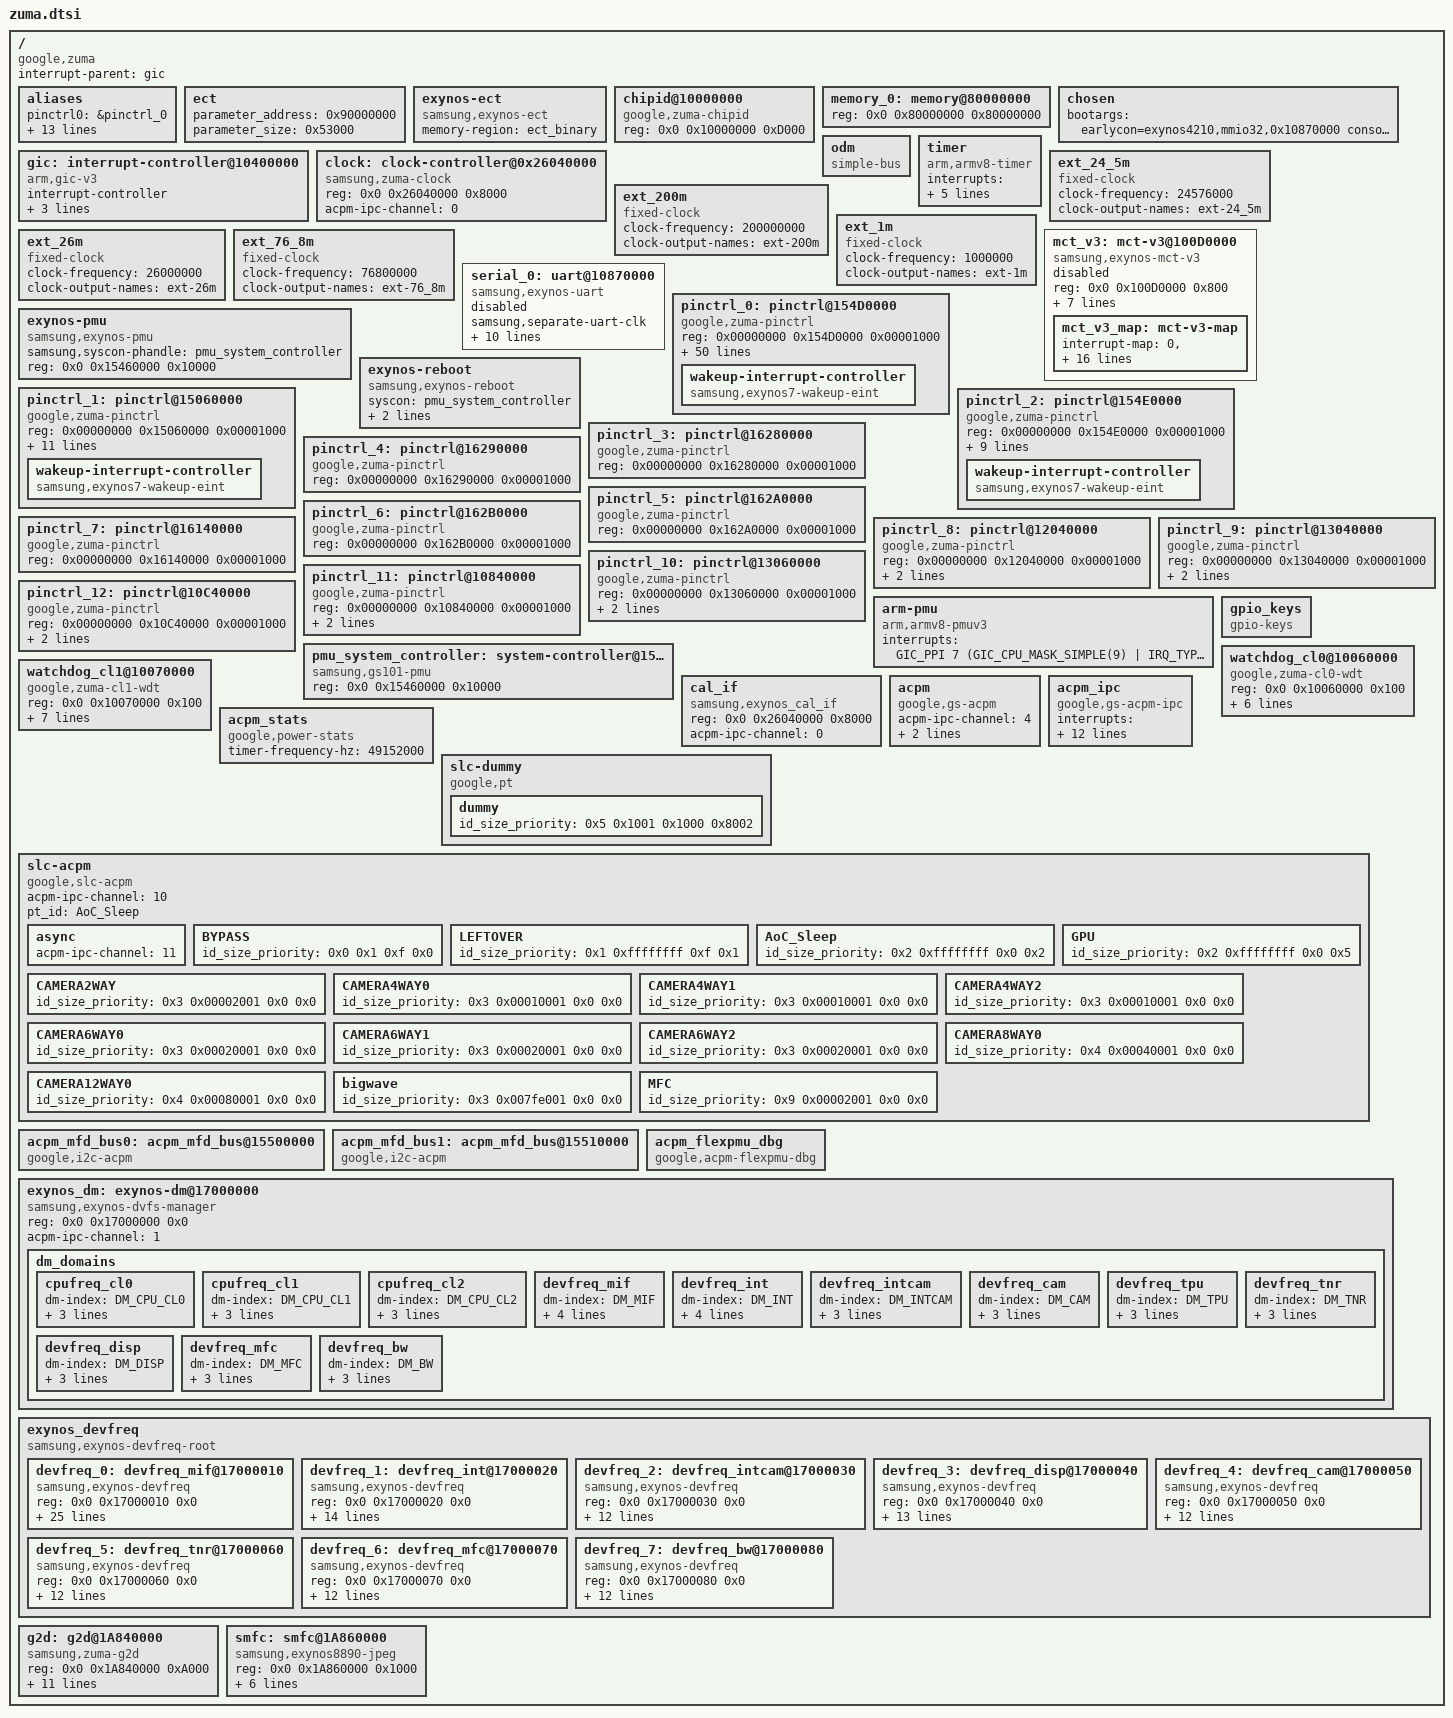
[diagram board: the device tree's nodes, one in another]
// SPDX-License-Identifier: GPL-2.0-only
/*
 * Copyright 2022 Google LLC.
 *
 */

#include <dt-bindings/gpio/gpio.h>
#include <dt-bindings/interrupt-controller/arm-gic.h>
#include <dt-bindings/interrupt-controller/zuma.h>
#include <dt-bindings/clock/zuma.h>
#include <dt-bindings/soc/google/zuma-dm.h>
#include <dt-bindings/soc/google/zuma-devfreq.h>
#include <dt-bindings/soc/google/zuma-pm-qos.h>
#include "zuma-rmem.dtsi"
#include "gs101-trusty.dtsi"
#include "zuma-gpu.dtsi"
#include "zuma-cpu.dtsi"
#include "zuma-bigw.dtsi"
#include "zuma-bts.dtsi"
#include "zuma-drm-dpu.dtsi"
#include "zuma-dma-heap.dtsi"
#include "zuma-gsa.dtsi"
#include "zuma-isp.dtsi"
#include "zuma-pinctrl.dtsi"
#include "zuma-usi.dtsi"
#include "zuma-debug.dtsi"
#include "zuma-aoc.dtsi"
#include "zuma-ufs.dtsi"
#include "zuma-usb.dtsi"
#include "zuma-pm-domains.dtsi"
#include "zuma-mfc.dtsi"
#include "zuma-tpu.dtsi"
#include "zuma-pcie.dtsi"
#include "zuma-gxp.dtsi"
#include "zuma-audio.dtsi"
#include "zuma-s2mpu.dtsi"

/ {
	compatible = "google,zuma";
	interrupt-parent = <&gic>;
	#address-cells = <2>;
	#size-cells = <1>;

	aliases {
		pinctrl0 = &pinctrl_0;
		pinctrl1 = &pinctrl_1;
		pinctrl2 = &pinctrl_2;
		pinctrl3 = &pinctrl_3;
		pinctrl4 = &pinctrl_4;
		pinctrl5 = &pinctrl_5;
		pinctrl6 = &pinctrl_6;
		pinctrl7 = &pinctrl_7;
		pinctrl8 = &pinctrl_8;
		pinctrl9 = &pinctrl_9;
		pinctrl10 = &pinctrl_10;
		pinctrl11 = &pinctrl_11;
		pinctrl12 = &pinctrl_12;
		uart0 = &serial_0;

	};

        ect {
                parameter_address = <0x90000000>;
                parameter_size = <0x53000>;
        };

        exynos-ect {
                compatible = "samsung,exynos-ect";
                memory-region = <&ect_binary>;
        };

	chipid@10000000 {
		compatible = "google,zuma-chipid";
		reg = <0x0 0x10000000 0xD000>;
	};

	memory_0: memory@80000000 {
		device_type = "memory";
		reg = <0x0 0x80000000 0x80000000>;
	};

	chosen: chosen {
		bootargs = "earlycon=exynos4210,mmio32,0x10870000 console=ttySAC0,115200n8 root=/dev/ram0 rw clocksource=arch_sys_counter androidboot.hardware=zuma androidboot.hardware.platform=zuma androidboot.selinux=permissive androidboot.debug_level=0x4948 clk_ignore_unused loop.max_part=7 coherent_pool=4M firmware_class.path=/vendor/firmware log_buf_len=256K irqaffinity=0rcupdate.rcu_expedited=1 printk.devkmsg=on swiotlb=noforce androidboot.slot_suffix=_a androidboot.secure_boot=NONE nokaslr exynos_drm.panel_name=samsung-emul sysrq_always_enabled no_console_suspend softlockup_panic=1 cpuidle.off=1";
	};

	odm: odm {
		compatible = "simple-bus";
		ranges;

		/* reserved for overlay by ODM */
	};

	gic: interrupt-controller@10400000 {
		compatible = "arm,gic-v3";
		#interrupt-cells = <3>;
		interrupt-controller;
		reg = <0x0 0x10400000 0x10000>,		/* GICD */
		      <0x0 0x10440000 0x200000>;	/* GICR * 8 */
		interrupts = <GIC_PPI 9 IRQ_TYPE_LEVEL_HIGH>;
	};

	timer {
		compatible = "arm,armv8-timer";
		interrupts = <GIC_PPI 13 (GIC_CPU_MASK_SIMPLE(9) | IRQ_TYPE_LEVEL_LOW)>,
			     <GIC_PPI 14 (GIC_CPU_MASK_SIMPLE(9) | IRQ_TYPE_LEVEL_LOW)>,
			     <GIC_PPI 11 (GIC_CPU_MASK_SIMPLE(9) | IRQ_TYPE_LEVEL_LOW)>,
			     <GIC_PPI 10 (GIC_CPU_MASK_SIMPLE(9) | IRQ_TYPE_LEVEL_LOW)>;
		clock-frequency = <24576000>;
	};

	clock: clock-controller@0x26040000 {
		compatible = "samsung,zuma-clock";
		reg = <0x0 0x26040000 0x8000>;
		#clock-cells = <1>;
		acpm-ipc-channel = <0>;
	};

	ext_24_5m: ext_24_5m {
		compatible = "fixed-clock";
		#clock-cells = <0>;
		clock-frequency = <24576000>;
		clock-output-names = "ext-24_5m";
	};

	ext_200m: ext_200m {
		compatible = "fixed-clock";
		#clock-cells = <0>;
		clock-frequency = <200000000>;
		clock-output-names = "ext-200m";
	};

	ext_26m: ext_26m {
		compatible = "fixed-clock";
		#clock-cells = <0>;
		clock-frequency = <26000000>;
		clock-output-names = "ext-26m";
	};

	ext_1m: ext_1m {
		compatible = "fixed-clock";
		#clock-cells = <0>;
		clock-frequency = <1000000>;
		clock-output-names = "ext-1m";
	};

	ext_76_8m: ext_76_8m {
		compatible = "fixed-clock";
		#clock-cells = <0>;
		clock-frequency = <76800000>;
		clock-output-names = "ext-76_8m";
	};

	mct_v3: mct-v3@100D0000 {
		compatible = "samsung,exynos-mct-v3";
		reg = <0x0 0x100D0000 0x800>;
		interrupt-controller;
		#interrupt-cells = <1>;
		interrupt-parent = <&mct_v3_map>;
		interrupts =    <0>, <1>, <2>, <3>,
				<4>, <5>, <6>, <7>,
				<8>, <9>, <10>, <11>;
		clocks = <&clock OSCCLK>, <&clock GATE_MCT>;
		clock-names = "fin_pll", "mct";
		div = <1>;
		use-clockevent-only;
		status = "disabled";

		mct_v3_map: mct-v3-map {
			#interrupt-cells = <1>;
			#address-cells = <0>;
			#size-cells = <0>;

			interrupt-map = <0 &gic 0 IRQ_MCT_L0_MISC IRQ_TYPE_LEVEL_HIGH>,
					<1 &gic 0 IRQ_MCT_L1_MISC IRQ_TYPE_LEVEL_HIGH>,
					<2 &gic 0 IRQ_MCT_L2_MISC IRQ_TYPE_LEVEL_HIGH>,
					<3 &gic 0 IRQ_MCT_L3_MISC IRQ_TYPE_LEVEL_HIGH>,
					<4 &gic 0 IRQ_MCT_L4_MISC IRQ_TYPE_LEVEL_HIGH>,
					<5 &gic 0 IRQ_MCT_L5_MISC IRQ_TYPE_LEVEL_HIGH>,
					<6 &gic 0 IRQ_MCT_L6_MISC IRQ_TYPE_LEVEL_HIGH>,
					<7 &gic 0 IRQ_MCT_L7_MISC IRQ_TYPE_LEVEL_HIGH>,
					<8 &gic 0 IRQ_MCT_L8_MISC IRQ_TYPE_LEVEL_HIGH>;

		};
	};

	serial_0: uart@10870000 {
		compatible = "samsung,exynos-uart";
		samsung,separate-uart-clk;
		samsung,usi-serial-v2;
		samsung,dbg-uart-ch;
		samsung,dbg-uart-baud = <115200>;
		samsung,dbg-word-len = <8>;
		reg-io-width = <4>;
		reg = <0x0 0x10870000 0x100>;
		samsung,fifo-size = <256>;
		interrupts = <GIC_SPI IRQ_USI0_UART_PERIC0 IRQ_TYPE_LEVEL_HIGH>;
		clocks = <&ext_200m>, <&ext_200m>;
		clock-names = "gate_uart_clk0", "ipclk_uart0";
		status = "disabled";
	};

	/* GPIO_ALIVE */
	pinctrl_0: pinctrl@154D0000 {
		compatible = "google,zuma-pinctrl";
		reg = <0x00000000 0x154D0000 0x00001000>;
		interrupts = <GIC_SPI IRQ_ALIVE_EINT0 IRQ_TYPE_LEVEL_HIGH>,
		     <GIC_SPI IRQ_ALIVE_EINT1 IRQ_TYPE_LEVEL_HIGH>,
		     <GIC_SPI IRQ_ALIVE_EINT2 IRQ_TYPE_LEVEL_HIGH>,
		     <GIC_SPI IRQ_ALIVE_EINT3 IRQ_TYPE_LEVEL_HIGH>,
		     <GIC_SPI IRQ_ALIVE_EINT4 IRQ_TYPE_LEVEL_HIGH>,
		     <GIC_SPI IRQ_ALIVE_EINT5 IRQ_TYPE_LEVEL_HIGH>,
		     <GIC_SPI IRQ_ALIVE_EINT6 IRQ_TYPE_LEVEL_HIGH>,
		     <GIC_SPI IRQ_ALIVE_EINT7 IRQ_TYPE_LEVEL_HIGH>,
		     <GIC_SPI IRQ_ALIVE_EINT8 IRQ_TYPE_LEVEL_HIGH>,
		     <GIC_SPI IRQ_ALIVE_EINT9 IRQ_TYPE_LEVEL_HIGH>,
		     <GIC_SPI IRQ_ALIVE_EINT10 IRQ_TYPE_LEVEL_HIGH>,
		     <GIC_SPI IRQ_ALIVE_EINT11 IRQ_TYPE_LEVEL_HIGH>,
		     <GIC_SPI IRQ_ALIVE_EINT12 IRQ_TYPE_LEVEL_HIGH>,
		     <GIC_SPI IRQ_ALIVE_EINT13 IRQ_TYPE_LEVEL_HIGH>,
		     <GIC_SPI IRQ_ALIVE_EINT14 IRQ_TYPE_LEVEL_HIGH>,
		     <GIC_SPI IRQ_ALIVE_EINT15 IRQ_TYPE_LEVEL_HIGH>,
		     <GIC_SPI IRQ_ALIVE_EINT16 IRQ_TYPE_LEVEL_HIGH>,
		     <GIC_SPI IRQ_ALIVE_EINT17 IRQ_TYPE_LEVEL_HIGH>,
		     <GIC_SPI IRQ_ALIVE_EINT18 IRQ_TYPE_LEVEL_HIGH>,
		     <GIC_SPI IRQ_ALIVE_EINT20 IRQ_TYPE_LEVEL_HIGH>,
		     <GIC_SPI IRQ_ALIVE_EINT21 IRQ_TYPE_LEVEL_HIGH>,
		     <GIC_SPI IRQ_ALIVE_EINT22 IRQ_TYPE_LEVEL_HIGH>,
		     <GIC_SPI IRQ_ALIVE_EINT23 IRQ_TYPE_LEVEL_HIGH>,
		     <GIC_SPI IRQ_ALIVE_EINT24 IRQ_TYPE_LEVEL_HIGH>,
		     <GIC_SPI IRQ_ALIVE_EINT25 IRQ_TYPE_LEVEL_HIGH>,
		     <GIC_SPI IRQ_ALIVE_EINT26 IRQ_TYPE_LEVEL_HIGH>,
		     <GIC_SPI IRQ_ALIVE_EINT27 IRQ_TYPE_LEVEL_HIGH>,
		     <GIC_SPI IRQ_ALIVE_EINT28 IRQ_TYPE_LEVEL_HIGH>,
		     <GIC_SPI IRQ_ALIVE_EINT29 IRQ_TYPE_LEVEL_HIGH>,
		     <GIC_SPI IRQ_ALIVE_EINT30 IRQ_TYPE_LEVEL_HIGH>,
		     <GIC_SPI IRQ_ALIVE_EINT31 IRQ_TYPE_LEVEL_HIGH>,
		     <GIC_SPI IRQ_ALIVE_EINT32 IRQ_TYPE_LEVEL_HIGH>,
		     <GIC_SPI IRQ_ALIVE_EINT33 IRQ_TYPE_LEVEL_HIGH>,
		     <GIC_SPI IRQ_ALIVE_EINT34 IRQ_TYPE_LEVEL_HIGH>,
		     <GIC_SPI IRQ_ALIVE_EINT35 IRQ_TYPE_LEVEL_HIGH>,
		     <GIC_SPI IRQ_ALIVE_EINT36 IRQ_TYPE_LEVEL_HIGH>,
		     <GIC_SPI IRQ_ALIVE_EINT37 IRQ_TYPE_LEVEL_HIGH>,
		     <GIC_SPI IRQ_ALIVE_EINT38 IRQ_TYPE_LEVEL_HIGH>,
		     <GIC_SPI IRQ_ALIVE_EINT39 IRQ_TYPE_LEVEL_HIGH>,
		     <GIC_SPI IRQ_ALIVE_EINT40 IRQ_TYPE_LEVEL_HIGH>,
		     <GIC_SPI IRQ_ALIVE_EINT41 IRQ_TYPE_LEVEL_HIGH>,
		     <GIC_SPI IRQ_ALIVE_EINT42 IRQ_TYPE_LEVEL_HIGH>,
		     <GIC_SPI IRQ_ALIVE_EINT43 IRQ_TYPE_LEVEL_HIGH>,
		     <GIC_SPI IRQ_ALIVE_EINT44 IRQ_TYPE_LEVEL_HIGH>,
		     <GIC_SPI IRQ_ALIVE_EINT45 IRQ_TYPE_LEVEL_HIGH>,
		     <GIC_SPI IRQ_ALIVE_EINT46 IRQ_TYPE_LEVEL_HIGH>,
		     <GIC_SPI IRQ_ALIVE_EINT47 IRQ_TYPE_LEVEL_HIGH>,
		     <GIC_SPI IRQ_ALIVE_EINT48 IRQ_TYPE_LEVEL_HIGH>,
		     <GIC_SPI IRQ_ALIVE_EINT49 IRQ_TYPE_LEVEL_HIGH>;


		wakeup-interrupt-controller {
			compatible = "samsung,exynos7-wakeup-eint";
		};
	};

	exynos-pmu {
		compatible = "samsung,exynos-pmu";
		samsung,syscon-phandle = <&pmu_system_controller>;
		reg = <0x0 0x15460000 0x10000>;
		reg-names = "pmu_alive";
	};

	exynos-reboot {
		compatible = "samsung,exynos-reboot";
		syscon = <&pmu_system_controller>;
		reboot-cmd-offset = <0x0810>;
		force-warm-reboot-on-thermal-shutdown;
	};

	/* GPIO_CUSTOM_ALIVE */
	pinctrl_1: pinctrl@15060000 {
		compatible = "google,zuma-pinctrl";
		reg = <0x00000000 0x15060000 0x00001000>;
		interrupts = <GIC_SPI IRQ_ALIVE_CUSTOM_EINT0 IRQ_TYPE_LEVEL_HIGH>,
			     <GIC_SPI IRQ_ALIVE_CUSTOM_EINT1 IRQ_TYPE_LEVEL_HIGH>,
			     <GIC_SPI IRQ_ALIVE_CUSTOM_EINT2 IRQ_TYPE_LEVEL_HIGH>,
			     <GIC_SPI IRQ_ALIVE_CUSTOM_EINT3 IRQ_TYPE_LEVEL_HIGH>,
			     <GIC_SPI IRQ_ALIVE_CUSTOM_EINT4 IRQ_TYPE_LEVEL_HIGH>,
			     <GIC_SPI IRQ_ALIVE_CUSTOM_EINT5 IRQ_TYPE_LEVEL_HIGH>,
			     <GIC_SPI IRQ_ALIVE_CUSTOM_EINT6 IRQ_TYPE_LEVEL_HIGH>,
			     <GIC_SPI IRQ_ALIVE_CUSTOM_EINT7 IRQ_TYPE_LEVEL_HIGH>,
			     <GIC_SPI IRQ_ALIVE_CUSTOM_EINT8 IRQ_TYPE_LEVEL_HIGH>,
			     <GIC_SPI IRQ_ALIVE_CUSTOM_EINT9 IRQ_TYPE_LEVEL_HIGH>;

			wakeup-interrupt-controller {
				compatible = "samsung,exynos7-wakeup-eint";
			};
	};

	/* GPIO_FAR_ALIVE */
	pinctrl_2: pinctrl@154E0000 {
		compatible = "google,zuma-pinctrl";
		reg = <0x00000000 0x154E0000 0x00001000>;
		interrupts = <GIC_SPI IRQ_ALIVE_EINT50 IRQ_TYPE_LEVEL_HIGH>,
			     <GIC_SPI IRQ_ALIVE_EINT51 IRQ_TYPE_LEVEL_HIGH>,
			     <GIC_SPI IRQ_ALIVE_EINT52 IRQ_TYPE_LEVEL_HIGH>,
			     <GIC_SPI IRQ_ALIVE_EINT53 IRQ_TYPE_LEVEL_HIGH>,
			     <GIC_SPI IRQ_ALIVE_EINT54 IRQ_TYPE_LEVEL_HIGH>,
			     <GIC_SPI IRQ_ALIVE_EINT55 IRQ_TYPE_LEVEL_HIGH>,
			     <GIC_SPI IRQ_ALIVE_EINT56 IRQ_TYPE_LEVEL_HIGH>,
			     <GIC_SPI IRQ_ALIVE_EINT57 IRQ_TYPE_LEVEL_HIGH>;

		wakeup-interrupt-controller {
			compatible = "samsung,exynos7-wakeup-eint";
		};
	};

	/* GPIO_GSACORE0 */
	pinctrl_3: pinctrl@16280000 {
		compatible = "google,zuma-pinctrl";
		reg = <0x00000000 0x16280000 0x00001000>;
	};

	/* GPIO_GSACORE1 */
	pinctrl_4: pinctrl@16290000 {
		compatible = "google,zuma-pinctrl";
		reg = <0x00000000 0x16290000 0x00001000>;
	};

	/* GPIO_GSACORE2 */
	pinctrl_5: pinctrl@162A0000 {
		compatible = "google,zuma-pinctrl";
		reg = <0x00000000 0x162A0000 0x00001000>;
	};

	/* GPIO_GSACORE3 */
	pinctrl_6: pinctrl@162B0000 {
		compatible = "google,zuma-pinctrl";
		reg = <0x00000000 0x162B0000 0x00001000>;
	};

	/* GPIO_GSACTRL */
	pinctrl_7: pinctrl@16140000 {
		compatible = "google,zuma-pinctrl";
		reg = <0x00000000 0x16140000 0x00001000>;
	};

	/* GPIO_HSI1 */
	pinctrl_8: pinctrl@12040000 {
		compatible = "google,zuma-pinctrl";
		reg = <0x00000000 0x12040000 0x00001000>;
		interrupts = <GIC_SPI IRQ_GPIO_HSI1_HSI1 IRQ_TYPE_LEVEL_HIGH>;
	};

	/* GPIO_HSI2 */
	 pinctrl_9: pinctrl@13040000 {
		compatible = "google,zuma-pinctrl";
		reg = <0x00000000 0x13040000 0x00001000>;
		interrupts = <GIC_SPI IRQ_GPIO_HSI2_HSI2 IRQ_TYPE_LEVEL_HIGH>;
	};

	/* GPIO_HSI2UFS */
	pinctrl_10: pinctrl@13060000 {
		compatible = "google,zuma-pinctrl";
		reg = <0x00000000 0x13060000 0x00001000>;
		interrupts = <GIC_SPI IRQ_GPIO_HSI2UFS_HSI2 IRQ_TYPE_LEVEL_HIGH>;
	};

	/* GPIO_PERIC0 */
	pinctrl_11: pinctrl@10840000 {
		compatible = "google,zuma-pinctrl";
		reg = <0x00000000 0x10840000 0x00001000>;
		interrupts = <GIC_SPI IRQ_GPIO_PERIC0_PERIC0 IRQ_TYPE_LEVEL_HIGH>;
	};

	/* GPIO_PERIC1 */
	pinctrl_12: pinctrl@10C40000 {
		compatible = "google,zuma-pinctrl";
		reg = <0x00000000 0x10C40000 0x00001000>;
		interrupts = <GIC_SPI IRQ_GPIO_PERIC1_PERIC1 IRQ_TYPE_LEVEL_HIGH>;
	};

	arm-pmu {
		compatible = "arm,armv8-pmuv3";
		interrupts = <GIC_PPI 7 (GIC_CPU_MASK_SIMPLE(9) | IRQ_TYPE_LEVEL_HIGH)>;
	};

	pmu_system_controller: system-controller@15460000 {
		compatible = "samsung,gs101-pmu", "syscon";
		reg = <0x0 0x15460000 0x10000>;
	};

	gpio_keys: gpio_keys {
		compatible = "gpio-keys";
	};

	watchdog_cl0@10060000 {
		compatible = "google,zuma-cl0-wdt";
		reg = <0x0 0x10060000 0x100>;
		interrupts = <GIC_SPI IRQ_WDT_CLUSTER0_MISC IRQ_TYPE_LEVEL_HIGH>;
		clocks = <&clock OSCCLK>, <&clock GATE_WDT_CL0>;
		clock-names = "rate_watchdog", "gate_watchdog";
		timeout-sec = <30>;
		samsung,syscon-phandle = <&pmu_system_controller>;
		index = <0>; /* if little cluster then index is 0*/
	};

	watchdog_cl1@10070000 {
		compatible = "google,zuma-cl1-wdt";
		reg = <0x0 0x10070000 0x100>;
		interrupts = <GIC_SPI IRQ_WDT_CLUSTER1_MISC IRQ_TYPE_LEVEL_HIGH>;
		clocks = <&clock OSCCLK>, <&clock GATE_WDT_CL1>;
		clock-names = "rate_watchdog", "gate_watchdog";
		timeout-sec = <30>;
		samsung,syscon-phandle = <&pmu_system_controller>;
		index = <1>; /* if little cluster then index is 0*/
		use_multistage_wdt; /* Use FIQ debug watchdog */
	};

	cal_if: cal_if {
		compatible = "samsung,exynos_cal_if";
		reg = <0x0 0x26040000 0x8000>;
		acpm-ipc-channel = <0>;
	};

	acpm {
		compatible = "google,gs-acpm";
		#address-cells = <2>;
		#size-cells = <1>;
		acpm-ipc-channel = <4>;
		reg = <0x0 0x15440000 0x1000>;	/* TIMER_APM */
		reg-names = "timer_apm";
		peritimer-cnt = <0xFFFF>;
	};

	acpm_ipc {
		compatible = "google,gs-acpm-ipc";
		#address-cells = <2>;
		#size-cells = <1>;
		interrupts = <GIC_SPI IRQ_MAILBOX_APM2AP_ALIVE IRQ_TYPE_LEVEL_HIGH>;
		reg = <0x0 0x15110000 0x01000>,	/* AP2APM MAILBOX */
		      <0x0 0x15700000 0x58000>,	/* APM SRAM region from AP view */
		      <0x0 0x1542048C 0x00014>;	/* SYSREG_APM.ALIVE_FRC_CTRL0 */
		initdata-base = <0xA000>;
		debug-log-level = <0>;
		logging-period = <500>;
		dump-base = <0x15705000>;	/* Non-secure world base addr */
		dump-size = <0x55000>;		/* Non-secure SRAM size: 320KB */
		acpm-ipc-channel = <12>;
		fvmap_addr = <0x31000>;
		panic-action = <GO_WATCHDOG_ID>;
	};

	acpm_stats {
		compatible = "google,power-stats";
		timer-frequency-hz = <49152000>;
	};

	slc-dummy {
		compatible = "google,pt";
		dummy {
			id_size_priority = <0x5 0x1001 0x1000 0x8002>;
		};
	};

	slc-acpm {
		compatible = "google,slc-acpm";
		acpm-ipc-channel = <10>;
		pt_id = "AoC_Sleep"; /* for testing */
		async {
			acpm-ipc-channel = <11>;
		};
		BYPASS {
			/* vptid 0, size 0, priority 15 (lowest), pbha 0 */
			id_size_priority = <0x0 0x1 0xf 0x0>;
		};
		LEFTOVER {
			/* vptid 1, all sizes, priority 15 (lowest), pbha 1 */
			id_size_priority = <0x1 0xffffffff 0xf 0x1>;
		};
		AoC_Sleep {
			/* vptid 2, size 0, priority 0 (highest), pbha 2 */
			id_size_priority = <0x2 0xffffffff 0x0 0x2>;
		};
		GPU {
			/* vptid 2, all sizes, priority 0 (highest), pbha 5 */
			id_size_priority = <0x2 0xffffffff 0x0 0x5>;
		};
		CAMERA2WAY {
			/* vptid 3, size 512KB, priority 0 (highest), pbha 0 */
			id_size_priority = <0x3 0x00002001 0x0 0x0>;
		};
		CAMERA4WAY0 {
			/* vptid 3, size 1024KB, priority 0 (highest), pbha 0 */
			id_size_priority = <0x3 0x00010001 0x0 0x0>;
		};
		CAMERA4WAY1 {
			/* vptid 3, size 1024KB, priority 0 (highest), pbha 0 */
			id_size_priority = <0x3 0x00010001 0x0 0x0>;
		};
		CAMERA4WAY2 {
			/* vptid 3, size 1024KB, priority 0 (highest), pbha 0 */
			id_size_priority = <0x3 0x00010001 0x0 0x0>;
		};
		CAMERA6WAY0 {
			/* vptid 3, size 1536KB, priority 0 (highest), pbha 0 */
			id_size_priority = <0x3 0x00020001 0x0 0x0>;
		};
		CAMERA6WAY1 {
			/* vptid 3, size 1536KB, priority 0 (highest), pbha 0 */
			id_size_priority = <0x3 0x00020001 0x0 0x0>;
		};
		CAMERA6WAY2 {
			/* vptid 3, size 1536KB, priority 0 (highest), pbha 0 */
			id_size_priority = <0x3 0x00020001 0x0 0x0>;
		};
		CAMERA8WAY0 {
			/* vptid 4, size 2048KB, priority 0 (highest), pbha 0 */
			id_size_priority = <0x4 0x00040001 0x0 0x0>;
		};
		CAMERA12WAY0 {
			/* vptid 4, size 3072KB, priority 0 (highest), pbha 0 */
			id_size_priority = <0x4 0x00080001 0x0 0x0>;
		};
		bigwave {
			/* vptid 3, 512KB-8MB size, priority 0, pbha 0 */
			id_size_priority = <0x3 0x007fe001 0x0 0x0>;
		};
		MFC {
			/* vptid 9, 2*256KB, priority 0 (highest), pbha ? */
			id_size_priority = <0x9 0x00002001 0x0 0x0>;
		};
	};

	acpm_mfd_bus0: acpm_mfd_bus@15500000 {
		compatible = "google,i2c-acpm";
		status = "okay";
	};

	acpm_mfd_bus1: acpm_mfd_bus@15510000 {
		compatible = "google,i2c-acpm";
		status = "okay";
	};

	acpm_flexpmu_dbg {
		compatible = "google,acpm-flexpmu-dbg";
	};

	exynos_dm: exynos-dm@17000000 {
		compatible = "samsung,exynos-dvfs-manager";
		reg = <0x0 0x17000000 0x0>;
		acpm-ipc-channel = <1>;
		dm_domains {
			cpufreq_cl0 {
				dm-index = <DM_CPU_CL0>;
				available = "true";
				cal_id = <ACPM_DVFS_CPUCL0>;
				dm_type_name = "dm_cpu_cl0";
			};
			cpufreq_cl1 {
				dm-index = <DM_CPU_CL1>;
				available = "true";
				cal_id = <ACPM_DVFS_CPUCL1>;
				dm_type_name = "dm_cpu_cl1";
			};
			cpufreq_cl2 {
				dm-index = <DM_CPU_CL2>;
				available = "true";
				cal_id = <ACPM_DVFS_CPUCL2>;
				dm_type_name = "dm_cpu_cl2";
			};
			devfreq_mif {
				dm-index = <DM_MIF>;
				available = "true";
				policy_use = "true";
				cal_id = <ACPM_DVFS_MIF>;
				dm_type_name = "dm_mif";
			};
			devfreq_int {
				dm-index = <DM_INT>;
				available = "true";
				policy_use = "true";
				cal_id = <ACPM_DVFS_INT>;
				dm_type_name = "dm_int";
			};
			devfreq_intcam {
				dm-index = <DM_INTCAM>;
				available = "true";
				cal_id = <ACPM_DVFS_INTCAM>;
				dm_type_name = "dm_intcam";
			};
			devfreq_cam {
				dm-index = <DM_CAM>;
				available = "true";
				cal_id = <ACPM_DVFS_CAM>;
				dm_type_name = "dm_cam";
			};
			devfreq_tpu {
				dm-index = <DM_TPU>;
				available = "true";
				cal_id = <ACPM_DVFS_TPU>;
				dm_type_name = "dm_tpu";
			};
			devfreq_tnr {
				dm-index = <DM_TNR>;
				available = "true";
				cal_id = <ACPM_DVFS_TNR>;
				dm_type_name = "dm_tnr";
			};
			devfreq_disp {
				dm-index = <DM_DISP>;
				available = "true";
				cal_id = <ACPM_DVFS_DISP>;
				dm_type_name = "dm_disp";
			};
			devfreq_mfc {
				dm-index = <DM_MFC>;
				available = "true";
				cal_id = <ACPM_DVFS_MFC>;
				dm_type_name = "dm_mfc";
			};
			devfreq_bw {
				dm-index = <DM_BW>;
				available = "true";
				cal_id = <ACPM_DVFS_BW>;
				dm_type_name = "dm_bw";
			};
		};
	};

	exynos_devfreq {
		compatible = "samsung,exynos-devfreq-root";
		#address-cells = <2>;
		#size-cells = <1>;
		ranges;
		devfreq_0: devfreq_mif@17000010 {
			compatible = "samsung,exynos-devfreq";
			reg = <0x0 0x17000010 0x0>;
			devfreq_type = <DEVFREQ_MIF>;
			devfreq_domain_name = "MIF";
			pm_qos_class = <PM_QOS_BUS_THROUGHPUT>;
			pm_qos_class_max = <PM_QOS_BUS_THROUGHPUT_MAX>;
			ess_flag = <ESS_FLAG_MIF>;
			dm-index = <DM_MIF>;
			clocks = <&clock UMUX_MIF_DDRPHY2X>;
			clock-names = "DEVFREQ";

			/* Delay time */
			use_delay_time = "false";

			/* FIXME: limit a max_freq to L1(3172MHz) */
			freq_info = <421000 421000 421000 421000
					3172000 1014000>;
			/* initial_freq, default_qos, suspend_freq,
			min_freq, max_freq, reboot_freq */

			/* governor data */
			governor = <SIMPLE_INTERACTIVE>;

			dfs_id = <ACPM_DVFS_MIF>;
			acpm-ipc-channel = <1>;
			use_acpm = "true";

			/* ALT-DVFS */
			use_get_dev = "true";
			um_count = <4 4>;
			um_list = <
				/* PPC_CPUCL0_D0_EVENT PPC_CPUCL0_D1_EVENT */
				0x26210000 0x26220000
				/* PPC_CPUCL0_D2_EVENT PPC_CPUCL0_D3_EVENT */
				0x26230000 0x26240000
				/* PPC_NOCL1A_M0_EVENT PPC_NOCL1A_M1_EVENT */
				0x26260000 0x26270000
				/* PPC_NOCL1A_M2_EVENT PPC_NOCL1A_M3_EVENT */
				0x26280000 0x26290000
			>;

			use_alt_dvfs;
			polling_ms = <0>;
			target_load = <20 40>;
			min_sample_time = <20>;
			hold_sample_time = <60>;
			hispeed_load = <100>;
			hispeed_freq = <1352000>;
		};

		devfreq_1: devfreq_int@17000020 {
			compatible = "samsung,exynos-devfreq";
			reg = <0x0 0x17000020 0x0>;
			devfreq_type = <DEVFREQ_INT>;
			devfreq_domain_name = "INT";
			pm_qos_class = <PM_QOS_DEVICE_THROUGHPUT>;
			pm_qos_class_max = <PM_QOS_DEVICE_THROUGHPUT_MAX>;
			ess_flag = <ESS_FLAG_INT>;
			dm-index = <DM_INT>;

			/* Delay time */
			use_delay_time = "false";

			freq_info = <178000 178000 178000 178000
					1066000 1066000>;
			/* <initial_freq, default_qos, suspend_freq, min,
			max, reboot_freq> */

			/* governor data */
			governor = <SIMPLE_INTERACTIVE>;

			bts_update = "false";
			dfs_id = <ACPM_DVFS_INT>;
			acpm-ipc-channel = <1>;
			use_acpm = "true";
		};

		devfreq_2: devfreq_intcam@17000030 {
			compatible = "samsung,exynos-devfreq";
			reg = <0x0 0x17000030 0x0>;
			devfreq_type = <DEVFREQ_INTCAM>;
			devfreq_domain_name = "INTCAM";
			pm_qos_class = <PM_QOS_INTCAM_THROUGHPUT>;
			pm_qos_class_max = <PM_QOS_INTCAM_THROUGHPUT_MAX>;
			ess_flag = <ESS_FLAG_INTCAM>;
			dm-index = <DM_INTCAM>;

			/* Delay time */
			use_delay_time = "false";

			freq_info = <67000 67000 67000 67000 664000 664000>;
			/* <initial_freq, default_qos, suspend_freq, min,
			max, reboot_freq> */

			/* governor data */
			governor = <SIMPLE_INTERACTIVE>;

			bts_update = "false";
			dfs_id = <ACPM_DVFS_INTCAM>;
		};

		devfreq_3: devfreq_disp@17000040 {
			compatible = "samsung,exynos-devfreq";
			reg = <0x0 0x17000040 0x0>;
			devfreq_type = <DEVFREQ_DISP>;
			devfreq_domain_name = "DISP";
			pm_qos_class = <PM_QOS_DISPLAY_THROUGHPUT>;
			pm_qos_class_max = <PM_QOS_DISPLAY_THROUGHPUT_MAX>;
			ess_flag = <ESS_FLAG_DISP>;
			dm-index = <DM_DISP>;

			/* Delay time */
			use_delay_time = "false";

			freq_info = <166000 166000 166000 166000
					664000 664000>;
			/* <initial_freq, default_qos, suspend_freq, min,
			max, reboot_freq> */

			/* governor data */
			governor = <SIMPLE_INTERACTIVE>;

			bts_update = "false";
			dfs_id = <ACPM_DVFS_DISP>;
		};

		devfreq_4: devfreq_cam@17000050 {
			compatible = "samsung,exynos-devfreq";
			reg = <0x0 0x17000050 0x0>;
			devfreq_type = <DEVFREQ_CAM>;
			devfreq_domain_name = "CAM";
			pm_qos_class = <PM_QOS_CAM_THROUGHPUT>;
			pm_qos_class_max = <PM_QOS_CAM_THROUGHPUT_MAX>;
			ess_flag = <ESS_FLAG_ISP>;
			dm-index = <DM_CAM>;

			/* Delay time */
			use_delay_time = "false";

			freq_info = <67000 67000 67000 67000 711000 711000>;
			/* <initial, default_qos, suspend_freq, min,
			max, reboot_freq> */

			/* governor data */
			governor = <SIMPLE_INTERACTIVE>;

			bts_update = "false";

			dfs_id = <ACPM_DVFS_CAM>;
		};

		devfreq_5: devfreq_tnr@17000060 {
			compatible = "samsung,exynos-devfreq";
			reg = <0x0 0x17000060 0x0>;
			devfreq_type = <DEVFREQ_TNR>;
			devfreq_domain_name = "TNR";
			pm_qos_class = <PM_QOS_TNR_THROUGHPUT>;
			pm_qos_class_max = <PM_QOS_TNR_THROUGHPUT_MAX>;
			ess_flag = <ESS_FLAG_TNR>;
			dm-index = <DM_TNR>;

			/* Delay time */
			use_delay_time = "false";

			freq_info = <67000 67000 67000 67000 664000 664000>;
			/* <initial_freq, default_qos, suspend_freq, min,
			max, reboot_freq> */

			/* governor data */
			governor = <SIMPLE_INTERACTIVE>;

			bts_update = "false";
			dfs_id = <ACPM_DVFS_TNR>;
		};

		devfreq_6: devfreq_mfc@17000070 {
			compatible = "samsung,exynos-devfreq";
			reg = <0x0 0x17000070 0x0>;
			devfreq_type = <DEVFREQ_MFC>;
			devfreq_domain_name = "MFC";
			pm_qos_class = <PM_QOS_MFC_THROUGHPUT>;
			pm_qos_class_max = <PM_QOS_MFC_THROUGHPUT_MAX>;
			ess_flag = <ESS_FLAG_MFC>;
			dm-index = <DM_MFC>;

			/* Delay time */
			use_delay_time = "false";

			freq_info = <134000 134000 134000 134000
					711000 711000>;
			/* <initial_freq, default_qos, suspend_freq, min,
			max, reboot_freq> */

			/* governor data */
			governor = <SIMPLE_INTERACTIVE>;

			bts_update = "false";
			dfs_id = <ACPM_DVFS_MFC>;
		};

		devfreq_7: devfreq_bw@17000080 {
			compatible = "samsung,exynos-devfreq";
			reg = <0x0 0x17000080 0x0>;
			devfreq_type = <DEVFREQ_BW>;
			devfreq_domain_name = "BW";
			pm_qos_class = <PM_QOS_BW_THROUGHPUT>;
			pm_qos_class_max = <PM_QOS_BW_THROUGHPUT_MAX>;
			ess_flag = <ESS_FLAG_BW>;
			dm-index = <DM_BW>;

			/* Delay time */
			use_delay_time = "false";

			freq_info = <100000 100000 100000 100000
					620000 620000>;
			/* <initial_freq, default_qos, suspend_freq, min,
			max, reboot_freq> */

			/* governor data */
			governor = <SIMPLE_INTERACTIVE>;
			bts_update = "false";
			dfs_id = <ACPM_DVFS_BW>;
		};
	};

	g2d: g2d@1A840000 {
		compatible = "samsung,zuma-g2d";
		reg = <0x0 0x1A840000 0xA000>;
		interrupts = <0 IRQ_G2D_G2D IRQ_TYPE_LEVEL_HIGH>;
		samsung,iommu-group = <&iommu_group_g2d>;
		iommus = <&sysmmu_g2d>;
		clocks = <&clock GATE_G2D>;
		clock-names = "gate";
		samsung,tzmp;
		hw_ppc =
			/* sc_up none x1 x1/4 x1/9 x1/16 */
			<3800 3200 2100 2600 3300 3600 /* rgb32 non-rotated */
			3500 3600 2100 2700 3300 3800 /* rgb32 rotated */
			3700 3500 3600 4300 4300 3500 /* yuv2p non-rotated */
			2600 2800 3200 3900 4300 3600 /* yuv2p rotated */
			3600 2600 1400 900 1000 1000 /* sbwc non-rotated */
			2600 2600 1400 900 1000 1000 /* sbwc rotated */
			1600 3400 300 500 800 700 /* rgb afbc non-rotated */
			1400 3600 300 800 900 900 /* rgb afbc rotated */
			2900 2000 800 300 300 400 /* yuv afbc non-rotated */
			2600 2000 800 300 300 400 /* yuv afbc rotated */
			2800>; /* colorfill */

		g2d_dvfs_table = <533000 711000
				465000 400000
				332000 332000
				200000 200000
				100000 100000
				>;
		itmon,port = "G2D";
		itmon,dest = "G2D";
	};

	smfc: smfc@1A860000 {
		compatible = "samsung,exynos8890-jpeg";
		reg = <0x0 0x1A860000 0x1000>;
		interrupts = <0 IRQ_JPEG_G2D IRQ_TYPE_LEVEL_HIGH>;
		clocks = <&clock GATE_JPEG>;
		clock-names = "gate";
		power-domains = <&pd_g2d>;
		samsung,iommu-group = <&iommu_group_g2d>;
		iommus = <&sysmmu_g2d>;
		dma-coherent;
	};

};
